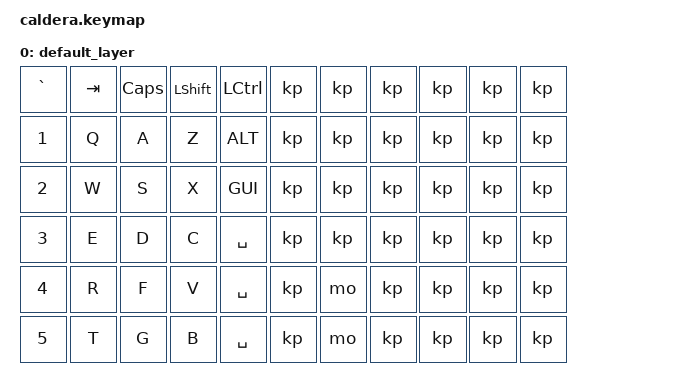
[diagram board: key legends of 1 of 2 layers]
#include <behaviors.dtsi>
#include <dt-bindings/zmk/keys.h>
#include <dt-bindings/zmk/bt.h>

/ {
        keymap {
                compatible = "zmk,keymap";

                default_layer {
// ---------------------------------------------------------------------------------
// |   `  |  1  |  2  |  3  |  4  |  5  |     |  6  |  7  |  8  |  9  |  0  | BKSP |
// |  TAB |  Q  |  W  |  E  |  R  |  T  |     |  Y  |  U  |  I  |  O  |  P  |  \   |
// | CAPS |  A  |  S  |  D  |  F  |  G  |     |  H  |  J  |  K  |  L  |  ;  |  ENT |
// | SHFT |  Z  |  X  |  C  |  V  |  B  |     |  N  |  M  |  ,  |  .  |  /  | APOS |
// | CTRL | ALT | GUI | SPC | SPC | SPC |     | SPC | LOW |LARW |DARW |UARW | RARW |
                        bindings = <
   &kp GRAVE  &kp TAB  &kp CAPS  &kp LSHIFT  &kp LCTRL                    &kp        &kp     &kp        &kp       &kp       &kp     
   &kp N1     &kp Q    &kp A     &kp Z       &kp ALT                      &kp        &kp     &kp        &kp       &kp       &kp 
   &kp N2     &kp W    &kp S     &kp X       &kp GUI                      &kp        &kp     &kp        &kp       &kp       &kp 
   &kp N3     &kp E    &kp D     &kp C       &kp SPC                      &kp        &kp     &kp        &kp       &kp       &kp 
   &kp N4     &kp R    &kp F     &kp V       &kp SPC                      &kp        &mo     &kp        &kp       &kp       &kp 
   &kp N5     &kp T    &kp G     &kp B       &kp SPC                      &kp        &mo     &kp        &kp       &kp       &kp 
                        >;
                };
                lower_layer {
// ------------------------------------------------------------------------------------------------------------
// |       |  BT1  |  BT2  |  BT3  |  BT4  |  BT5  |          |       |       |       |       |       | BTCLR |
// |       |       |       |       |       |       |          |       |       |       |       |       |       |
// |       |       |       | LPAR  | RPAR  |       |          |       | LBKT  | RBKT  |       |       |       |
// |       |       |       |       |       |       |          |       |       |       |       |       |       |
                        bindings = <
   &trans    &bt BT_SEL 0   &bt BT_SEL 1   &bt BT_SEL 2   &bt BT_SEL 3   &bt BT_SEL 4           &trans    &trans    &trans   &trans   &trans  &bt BT_CLR
   &trans    &trans         &trans         &trans         &trans         &trans                 &trans    &trans    &trans   &trans   &trans  &trans
   &trans    &trans         &trans         &kp LPAR       &kp RPAR       &trans                 &trans    &kp LBKT  &kp RBKT &kp MINUS   &kp EQUAL  &trans
   &trans    &trans         &trans         &trans         &trans         &trans                 &trans    &trans    &trans   &trans   &trans  &trans
                        >;
                };
        };
};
